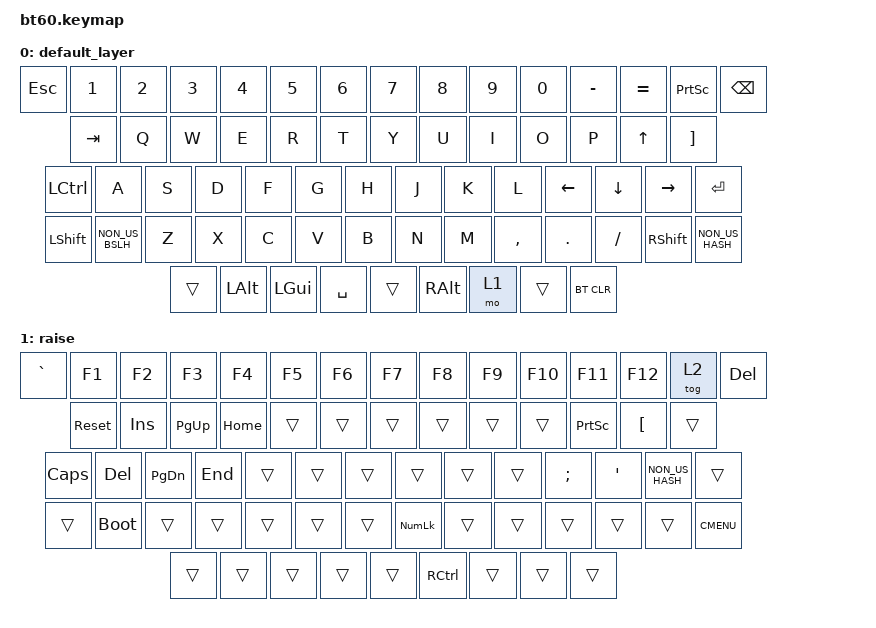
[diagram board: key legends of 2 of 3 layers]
#include <behaviors.dtsi>
#include <dt-bindings/zmk/keys.h>
#include <dt-bindings/zmk/bt.h>

/ {
	keymap {
		compatible = "zmk,keymap";

		default_layer {
				// -----------------------------------------------------------------------------------------------
				// | ESC |  1  |  2  |  3  |  4  |  5  |  6  |  7  |  8  |  9  |  0  |  -  |  =  | PSCRN | BKSP  |
				// | TAB  |  Q  |  W  |  E  |  R  |  T  |  Y  |  U  |  I  |  O  |  P  |  [  |  ]  |              |
				// | CAPS  |  A  |  S  |  D  |  F  |  G  |  H  |  J  |  K  |  L  |  ;  |  '  |  #   |   ENTER    |
				// | SHIFT |  NUBS  |  Z  |  X  |  C  |  V  |  B  |  N  |  M  |  ,  |  .  | /   | SHIFT |  NUHS  | 
				// |  CTL  |  WIN  |  ALT  |                     SPACE            |   ALT   |  1  | MENU | CTRL  |
				// -----------------------------------------------------------------------------------------------
			bindings = <
				&kp ESC &kp N1 &kp N2 &kp N3 &kp N4 &kp N5 &kp N6 &kp N7 &kp N8 &kp N9 &kp N0 &kp MINUS &kp EQUAL &kp PSCRN &kp BSPC
				&kp TAB &kp Q &kp W &kp E &kp R &kp T &kp Y &kp U &kp I &kp O &kp P &kp UP &kp RBKT
				&kp LCTRL &kp A &kp S &kp D &kp F &kp G &kp H &kp J &kp K &kp L &kp LEFT &kp DOWN &kp RIGHT &kp RET
				&kp LSHFT &kp NON_US_BSLH &kp Z &kp X &kp C &kp V &kp B &kp N &kp M &kp COMMA &kp DOT &kp FSLH &kp RSHFT &kp NON_US_HASH
				&trans &kp LALT &kp LGUI                    &kp SPACE                    &trans &kp RALT &mo 1 &trans &bt BT_CLR
			>;
			sensor-bindings = <&inc_dec_kp C_VOL_UP C_VOL_DN>;
		};
		raise {
			bindings = <
				&kp GRAVE &kp F1 &kp F2 &kp F3 &kp F4 &kp F5 &kp F6 &kp F7 &kp F8 &kp F9 &kp F10 &kp F11 &kp F12 &tog 2 &kp DEL
				&sys_reset &kp INS &kp PG_UP &kp HOME &trans &trans &trans &trans &trans &trans &kp PSCRN &kp LBKT &trans
				&kp CLCK &kp DEL &kp PG_DN &kp END &trans &trans &trans &trans &trans &trans &kp SEMI &kp SQT &kp NON_US_HASH &trans
				&trans &bootloader &trans &trans &trans &trans &trans &kp KP_NLCK &trans &trans &trans &trans &trans &kp K_CMENU
				&trans &trans &trans                    &trans                      &trans &kp RCTRL &trans &trans &trans
			>;
			sensor-bindings = <&inc_dec_kp C_VOL_UP C_VOL_DN>;
		};
		numpad_bt {
			bindings = <
				&trans &trans &trans &trans &trans &trans &trans &kp KP_N7 &kp KP_N8 &kp KP_N9 &trans &trans &trans &trans &trans
				&trans &trans &trans &trans &trans &trans &trans &kp KP_N4 &kp KP_N5 &kp KP_N6 &trans &trans &trans &trans
				&trans &trans &trans &trans &trans &trans &kp KP_N1 &kp KP_N2 &kp KP_N3 &trans &trans &trans &trans &trans
				&trans &trans &trans &trans &trans &trans &trans &kp KP_N0 &trans &trans &trans &trans &trans &trans
				&trans &trans &trans                    &trans                      &trans &trans &trans &trans &trans
			>;
			sensor-bindings = <&inc_dec_kp C_VOL_UP C_VOL_DN>;
		};
	};
};

// &kp SQT -> Ä ä
// &kp LBKT -> Ü ü
// &kp SEMI -> Ö ö
// &reset, &bootloader -> https://zmk.dev/docs/behaviors/reset
// layers -> https://zmk.dev/docs/behaviors/layers
// keycodes -> https://zmk.dev/docs/codes
// &bt BT_SEL 0 &bt BT_SEL 1 &bt BT_CLR &bt BT_PRV &bt BT_NXT
